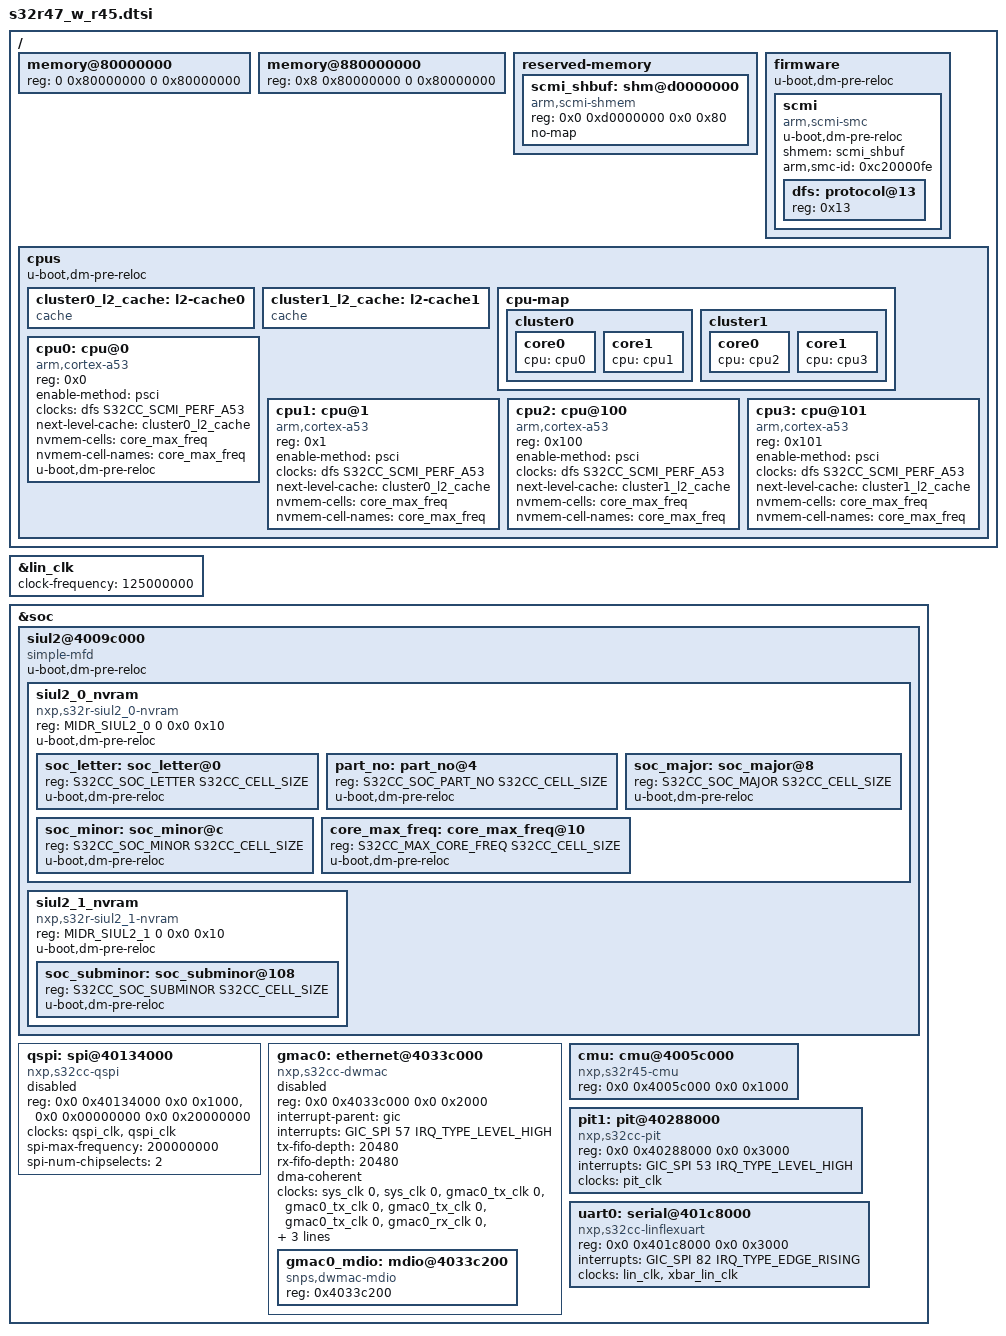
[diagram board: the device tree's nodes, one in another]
// SPDX-License-Identifier: (GPL-2.0+ OR BSD-3-Clause)
/*
 * Device Tree Include file compatibility layer between NXP R47 SoC
 * and R45 EVB board.
 *
 * Copyright 2025 NXP
 */

#include <dt-bindings/pinctrl/s32cc-pinfunc.h>
#include <dt-bindings/perf/s32cc-scmi-perf.h>

/ {
	/delete-node/ memory@60000000;

	memory@80000000 {
		device_type = "memory";
		reg = <0 0x80000000 0 0x80000000>;
	};

	memory@880000000 {
		device_type = "memory";
		reg = <0x8 0x80000000 0 0x80000000>;
	};
	/delete-node/ cpus;

	reserved-memory {
		scmi_shbuf: shm@d0000000 {
			compatible = "arm,scmi-shmem";
			reg = <0x0 0xd0000000 0x0 0x80>;
			no-map;
		};
	};

	firmware {
		u-boot,dm-pre-reloc;

		scmi: scmi {
			u-boot,dm-pre-reloc;
			compatible = "arm,scmi-smc";
			shmem = <&scmi_shbuf>;
			arm,smc-id = <0xc20000fe>;
			#address-cells = <1>;
			#size-cells = <0>;

			dfs: protocol@13 {
				reg = <0x13>;
				#clock-cells = <1>;
			};
		};
	};

	cpus {
		#address-cells = <1>;
		#size-cells = <0>;
		u-boot,dm-pre-reloc;

		cluster0_l2_cache: l2-cache0 {
			compatible = "cache";
		};

		cluster1_l2_cache: l2-cache1 {
			compatible = "cache";
		};

		cpu-map {
			cluster0 {
				core0 {
					cpu = <&cpu0>;
				};

				core1 {
					cpu = <&cpu1>;
				};
			};

			cluster1 {
				core0 {
					cpu = <&cpu2>;
				};

				core1 {
					cpu = <&cpu3>;
				};
			};
		};

		cpu0: cpu@0 {
			device_type = "cpu";
			compatible = "arm,cortex-a53";
			reg = <0x0>;
			enable-method = "psci";
			clocks = <&dfs S32CC_SCMI_PERF_A53>;
			next-level-cache = <&cluster0_l2_cache>;

			nvmem-cells = <&core_max_freq>;
			nvmem-cell-names = "core_max_freq";
			u-boot,dm-pre-reloc;
		};

		cpu1: cpu@1 {
			device_type = "cpu";
			compatible = "arm,cortex-a53";
			reg = <0x1>;
			enable-method = "psci";
			clocks = <&dfs S32CC_SCMI_PERF_A53>;
			next-level-cache = <&cluster0_l2_cache>;

			nvmem-cells = <&core_max_freq>;
			nvmem-cell-names = "core_max_freq";
		};

		cpu2: cpu@100 {
			device_type = "cpu";
			compatible = "arm,cortex-a53";
			reg = <0x100>;
			enable-method = "psci";
			clocks = <&dfs S32CC_SCMI_PERF_A53>;
			next-level-cache = <&cluster1_l2_cache>;

			nvmem-cells = <&core_max_freq>;
			nvmem-cell-names = "core_max_freq";
		};

		cpu3: cpu@101 {
			device_type = "cpu";
			compatible = "arm,cortex-a53";
			reg = <0x101>;
			enable-method = "psci";
			clocks = <&dfs S32CC_SCMI_PERF_A53>;
			next-level-cache = <&cluster1_l2_cache>;

			nvmem-cells = <&core_max_freq>;
			nvmem-cell-names = "core_max_freq";
		};
	};

};

&lin_clk {
	clock-frequency = <125000000>;
};

&soc {
	/delete-node/ siul2@40100000;
	siul2@4009c000 {
		compatible = "simple-mfd";
		u-boot,dm-pre-reloc;
		#address-cells = <2>;
		#size-cells = <2>;

		/* MIDR */
		ranges = <MIDR_SIUL2_0 0 0x0 0x4009c000 0x0 0x10>,
			<MIDR_SIUL2_1 0 0x0 0x4403c000 0x0 0x10>;

		siul2_0_nvram: siul2_0_nvram {
			reg = <MIDR_SIUL2_0 0 0x0 0x10>;
			#address-cells = <1>;
			#size-cells = <1>;

			compatible = "nxp,s32r-siul2_0-nvram";
			u-boot,dm-pre-reloc;

			soc_letter: soc_letter@0 {
				reg = <S32CC_SOC_LETTER S32CC_CELL_SIZE>;
				u-boot,dm-pre-reloc;
			};

			part_no: part_no@4 {
				reg = <S32CC_SOC_PART_NO S32CC_CELL_SIZE>;
				u-boot,dm-pre-reloc;
			};

			soc_major: soc_major@8 {
				reg = <S32CC_SOC_MAJOR S32CC_CELL_SIZE>;
				u-boot,dm-pre-reloc;
			};

			soc_minor: soc_minor@c {
				reg = <S32CC_SOC_MINOR S32CC_CELL_SIZE>;
				u-boot,dm-pre-reloc;
			};

			core_max_freq: core_max_freq@10 {
				reg = <S32CC_MAX_CORE_FREQ S32CC_CELL_SIZE>;
				u-boot,dm-pre-reloc;
			};
		};

		siul2_1_nvram {
			reg = <MIDR_SIUL2_1 0 0x0 0x10>;
			#address-cells = <1>;
			#size-cells = <1>;

			compatible = "nxp,s32r-siul2_1-nvram";
			u-boot,dm-pre-reloc;

			soc_subminor: soc_subminor@108 {
				reg = <S32CC_SOC_SUBMINOR S32CC_CELL_SIZE>;
				u-boot,dm-pre-reloc;
			};
		};
	};

	/delete-node/ spi@402d0000;
	qspi: spi@40134000 {
		compatible = "nxp,s32cc-qspi";
		#address-cells = <1>;
		#size-cells = <0>;
		reg = <0x0 0x40134000 0x0 0x1000>,
			<0x0 0x00000000 0x0 0x20000000>;
		reg-names = "QuadSPI", "QuadSPI-memory";
		clock-names = "qspi_en", "qspi";
		clocks = <&qspi_clk>, <&qspi_clk>;
		spi-max-frequency = <200000000>;
		spi-num-chipselects = <2>;
		status = "disabled";
	};

	gmac0: ethernet@4033c000 {
		compatible = "nxp,s32cc-dwmac";
		reg = <0x0 0x4033c000 0x0 0x2000>;
		interrupt-parent = <&gic>;
		interrupts = <GIC_SPI 57 IRQ_TYPE_LEVEL_HIGH>;
		interrupt-names = "macirq";
		tx-fifo-depth = <20480>;
		rx-fifo-depth = <20480>;
		status = "disabled";
		phy-names = "gmac_xpcs";
		dma-coherent;
		clocks = <&sys_clk 0>,
			<&sys_clk 0>,
			<&gmac0_tx_clk 0>,
			<&gmac0_tx_clk 0>,
			<&gmac0_tx_clk 0>,
			<&gmac0_tx_clk 0>,
			<&gmac0_rx_clk 0>,
			<&gmac0_rx_clk 0>,
			<&gmac0_rx_clk 0>,
			<&gmac0_rx_clk 0>,
			<&gmac_ts_clk 0>;
		clock-names = "stmmaceth", "pclk",
				"tx_sgmii", "tx_rgmii",
				"tx_rmii", "tx_mii",
				"rx_sgmii", "rx_rgmii",
				"rx_rmii", "rx_mii",
				"ptp_ref";
		#address-cells = <1>;
		#size-cells = <0>;
		phy-mode = "sgmii";

		gmac0_mdio: mdio@4033c200 {
			#address-cells = <1>;
			#size-cells = <0>;
			compatible = "snps,dwmac-mdio";
			reg = <0x4033c200>;
		};
	};

	/delete-node/ cmu@440cc000;
	/delete-node/ cmu@400d4000;
	cmu: cmu@4005c000 {
		reg = <0x0 0x4005c000 0x0 0x1000>;
		compatible = "nxp,s32r45-cmu";
	};

	/delete-node/ pit@440d8000;
	pit1: pit@40288000 {
		compatible = "nxp,s32cc-pit";
		reg = <0x0 0x40288000 0x0 0x3000>;
		interrupts = <GIC_SPI 53 IRQ_TYPE_LEVEL_HIGH>;
		clocks = <&pit_clk>;
		clock-names = "pit";
	};

	/delete-node/ serial@4048c000;
	uart0: serial@401c8000 {
		compatible = "nxp,s32cc-linflexuart", "fsl,s32v234-linflexuart";
		reg = <0x0 0x401c8000 0x0 0x3000>;
		interrupts = <GIC_SPI 82 IRQ_TYPE_EDGE_RISING>;
		clocks = <&lin_clk>, <&xbar_lin_clk>;
		clock-names = "lin", "ipg";
	};
};
